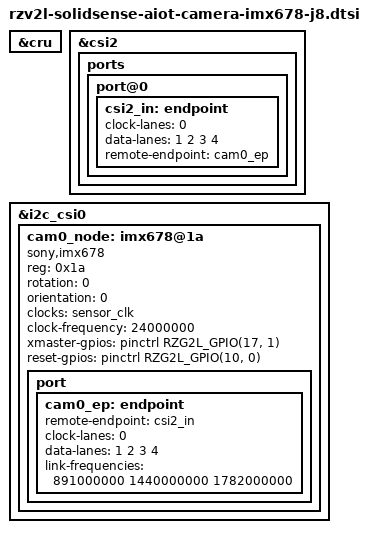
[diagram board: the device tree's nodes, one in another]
// SPDX-License-Identifier: (GPL-2.0-only OR BSD-2-Clause)
/*
 * SolidSense AIOT MIPI-CSI connector J8 (CAM0) with Sony IMX678, for the
 * RZ/V2L / RZ/G2L SoM (single CRU + CSI2).
 *
 * Shared fragment, included by the camera overlays. The including overlay
 * must provide /dts-v1/; /plugin/; and the dt-bindings headers
 * (gpio, rzg2l-pinctrl).
 *
 * Copyright (C) 2026 SolidRun Ltd.
 */

&cru {
	status = "okay";
};

&csi2 {
	status = "okay";

	ports {
		port@0 {
			csi2_in: endpoint {
				clock-lanes = <0>;
				data-lanes = <1 2 3 4>;
				remote-endpoint = <&cam0_ep>;
			};
		};
	};
};

/* [J8] CAM0 connector, sensor I2C on switch channel 0 (&i2c_csi0). */
&i2c_csi0 {
	#address-cells = <1>;
	#size-cells = <0>;

	cam0_node: imx678@1a {
		compatible = "sony,imx678";
		reg = <0x1a>;
		status = "okay";

		rotation = <0>;
		orientation = <0>;

		clocks = <&sensor_clk>;
		clock-names = "inclk";
		clock-frequency = <24000000>;

		/* CAM0_TRIG -> P17_1 */
		xmaster-gpios = <&pinctrl RZG2L_GPIO(17, 1) GPIO_ACTIVE_HIGH>;
		/* CAM0_RST# -> P10_0 */
		reset-gpios = <&pinctrl RZG2L_GPIO(10, 0) GPIO_ACTIVE_HIGH>;

		port {
			cam0_ep: endpoint {
				remote-endpoint = <&csi2_in>;
				clock-lanes = <0>;
				data-lanes = <1 2 3 4>;
				link-frequencies = /bits/ 64 <891000000 1440000000 1782000000>;
			};
		};
	};
};
